# cyw20829 register map
Vendor: Infineon Technologies; Series: CYW20829; File version: 1.0
CPU: CM33 r0p1, little endian, MPU, no FPU, VTOR, 3 interrupt priority bits
Registers are 32-bit, read-write, reset 0x0 unless marked. A register's access mark holds for its fields unless they carry their own. Offsets are from the block's base; [hi:lo] are bit positions; lines under a group give offsets from that group; {n}, {i} and the like mark numbered series.

## PPC — Peripheral Protection Controller
Base 0x40020000
0x00 CTL — PPC Control Registers
  [0] RESP_CFG — Response Configuration. This field configures the security violation response. 0 - Read-Zero Write Ignore (RZWI) 1 - Bus Error
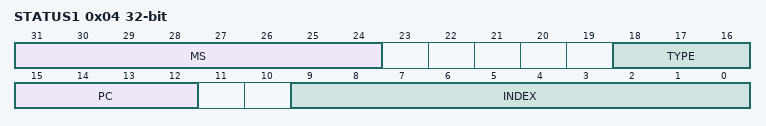
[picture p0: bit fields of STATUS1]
0x04 STATUS1 ro
  [31:24] MS — Indicates the Master ID of violating transfer.
  [18:16] TYPE
  [15:12] PC — Indicates the master interface transaction PC value when violation is detected. This field is only valid when INTR_PPC.SECURE_VIO=1.
  [9:0] INDEX — Index to indicate which peripheral region has first violated security access when INTR_PPC.SECURE_VIO=1. This field is only valid when INTR_PPC.SECURE_VIO=1. Note that when STATUS1.TYPE=AHB_ERROR (3'd5), this field is not valid.
0x08 STATUS2 ro
  [31:0] ADDR — Indicates the address of PPC violating transfer. STATUS2.ADDR status register is addition to PPC STATUS1 register. And all rules applicable for STATUS1 is applies to STATUS2 also.
0x0C LOCK_MASK — Locked Mask
  [31:0] LOCK_MASK — A mask that indicates which protection contexts are 'locked'. Once locked, a protection context cannot be unlocked until the next reset or power cycle. Bit i specifies the locked status for protection context i. 0: The protection context is unlocked. 1: The protection context is locked. When a PC is locked, the PPC_PC_MASK, PPC_NS_ATT and PPC_S_P_ATT register bits for peripheral regions to which this PC has access can no longer be modified (PPC_NS_P_ATT is not subject to these restrictions). The one exception to this is that PPC_PC_MASK bits associated with other protection contexts that are not themselves locked can still be cleared (but not set).
0x20 INTR_PPC — Interrupt
  [0] SECURE_VIO — HW sets this field to '1', when a security violation is detected.
0x24 INTR_PPC_SET — Interrupt set
  [0] SECURE_VIO — Write this field with '1' to set corresponding INTR_PPC field (a write of '0' has no effect).
0x28 INTR_PPC_MASK — Interrupt mask
  [0] SECURE_VIO — Mask for corresponding field in INTR_PPC register.
0x2C INTR_PPC_MASKED ro — Interrupt masked
  [0] SECURE_VIO — Logical AND of corresponding INTR_PPC and INTR_PPC_MASK fields.
{0x1000+4i} PC_MASK[{i}] (i=0..1023) reset 0xFFFFFFFF — Protection Context Mask
  [31:0] PC_MASK — A mask that indicates which protection contexts have access to a peripheral region. Bit i specifies the access for protection context i. 0: The protection context has no access to this region. 1: The protection context has access to this region, subject to secure and privilege attribute constraints setup in PPC_NS_ATT, PPC_S_P_ATT, PPC_NS_P_ATT registers)
{0x2000+4i} NS_ATT[{i}] (i=0..31) — Non-secure attribute
  [31:0] NS — Non-Secure. Each bit indicates whether access to a peripheral region must be secure or non-secure: IF SECURITY_AWARE=0 0 - allow only secure access to respective peripheral region. 1 - allow only non-secure access to respective peripheral region. IF SECURITY_AWARE=1 0 - allow only secure access to respective peripheral region. 1 - allows both secure and non-secure access to respective peripheral region. (Note that, depending on this setting the privilege access requirement for this region is specified in the corresponding PPC_S_P_ATT or PPC_NS_P_ATT register)
{0x2400+4i} S_P_ATT[{i}] (i=0..31) — Secure Privilege Attribute
  [31:0] S_P — Secure Privilege. Each bit indicates whether access to a secure peripheral region requires privilege: 0 - allow only secure privileged access to respective peripheral region. 1 - allow only secure unprivileged or privileged access to respective peripheral region.
{0x4000+4i} NS_P_ATT[{i}] (i=0..31) — Non-secure Privilege Attribute
  [31:0] NS_P — Non-Secure Privilege. Each bit indicates whether access to a non-secure peripheral region requires privilege: 0 - allow only non-secure privileged access to respective peripheral region. 1 - allow only non-secure unprivileged or privileged access to respective peripheral region.
{0x5000+4i} R_ADDR[{i}] (i=0..156) group — Region Address
  0x00 R_ADDR ro — Region Address
    [31:2] R_ADDR — This field specifies the base address of the peripheral region. The region size is defined by R_ATTR.R_SIZE. A region of n Bytes mus be n Byte aligned. Therefore, some of the lesser significant address bits of ADDR must be '0's. E.g., a 64KB address region (R_SIZE is '15') must be 64 KByte aligned, and R_ADDR[13:0] must be '0's.
{0x6000+4i} R_ATT[{i}] (i=0..156) group — Region Attribute
  0x00 R_ATT ro — Region Attribute
    [28:24] R_SIZE — This field specifies the size of the peripheral region: '0': Undefined. '1': 4 B region (this is the smallest region size). '2': 8 B region '3': 16 B region '4': 32 B region '5': 64 B region '6': 128 B region '7': 256 B region '8': 512 B region '9': 1 KB region '10': 2 KB region '11': 4 KB region '12': 8 KB region '13': 16 KB region '14': 32 KB region '15': 64 KB region '16': 128 KB region '17': 256 KB region '18': 512 KB region '19': 1 MB region '20': 2 MB region '21': 4 MB region '22': 8 MB region '23': 16 MB region '24': 32 MB region '25': 64 MB region '26': 128 MB region '27': 256 MB region '28': 512 MB region '29': 1 GB region '30': 2 GB region '31': 4 GB region
